# HDSC_HC32F146JX register map
Vendor: HDSC Co.Ltd; Series: ARMCM0P; File version: 1.2
CPU: CM0 r0p0, little endian, no MPU, no FPU, 3 interrupt priority bits
Registers are 8-bit, read-write, reset 0x0 unless marked. A register's access mark holds for its fields unless they carry their own. Offsets are from the block's base; [hi:lo] are bit positions; {n}, {i} and the like mark numbered series.

## EXTINT
Base 0x40030000
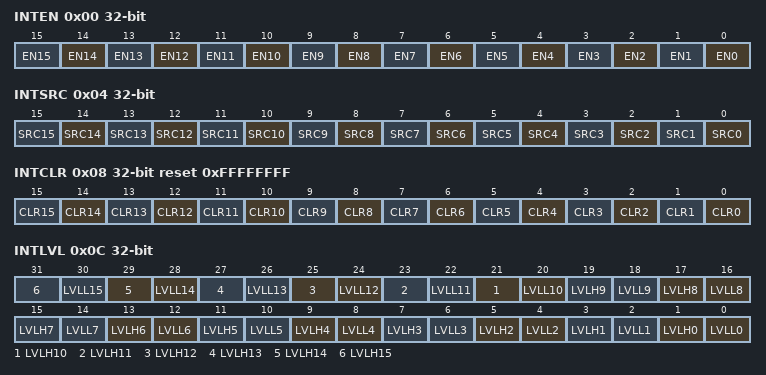
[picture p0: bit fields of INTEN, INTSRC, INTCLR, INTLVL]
0x00 INTEN 32-bit
  [n] EN{n} (n=0..15)
0x04 INTSRC 32-bit ro
  [n] SRC{n} (n=0..15)
0x08 INTCLR 32-bit reset 0xFFFFFFFF
  [n] CLR{n} (n=0..15)
0x0C INTLVL 32-bit
  [2n+1] LVLH{n} (n=0..15), [2n] LVLL{n} (n=0..15)
0x14 NMISRC 16-bit ro
  [0] SRC
0x18 NMICLR 16-bit reset 0x1
  [0] CLR

## FASTIO
Base 0xF8000000
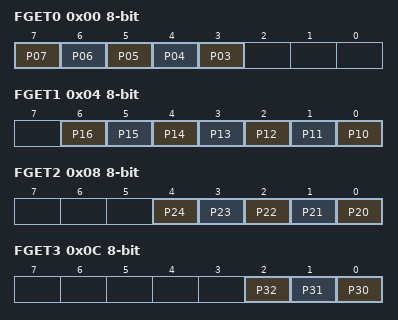
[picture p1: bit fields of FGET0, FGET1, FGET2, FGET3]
0x00 FGET0 ro
  [n] P{n:02} (n=3..7)
0x04 FGET1 ro
  [n-10] P{n} (n=10..16)
0x08 FGET2 ro
  [n-20] P{n} (n=20..24)
0x0C FGET3 ro
  [2] P32, [1] P31, [0] P30
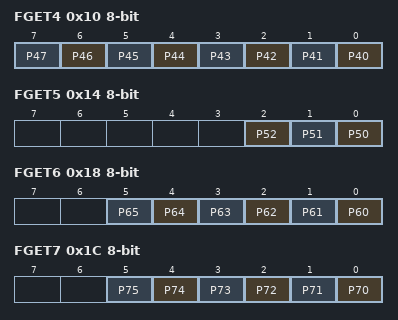
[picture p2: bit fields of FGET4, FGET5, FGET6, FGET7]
0x10 FGET4 ro
  [n-40] P{n} (n=40..47)
0x14 FGET5 ro
  [2] P52, [1] P51, [0] P50
0x18 FGET6 ro
  [n-60] P{n} (n=60..65)
0x1C FGET7 ro
  [n-70] P{n} (n=70..75)
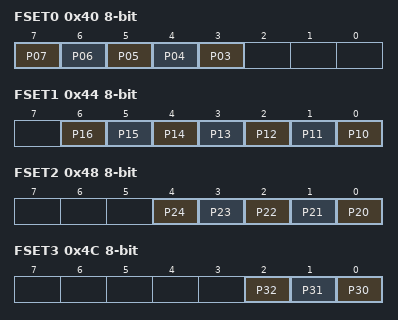
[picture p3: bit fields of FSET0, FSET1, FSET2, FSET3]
0x40 FSET0
  [n] P{n:02} (n=3..7)
0x44 FSET1
  [n-10] P{n} (n=10..16)
0x48 FSET2
  [n-20] P{n} (n=20..24)
0x4C FSET3
  [2] P32, [1] P31, [0] P30
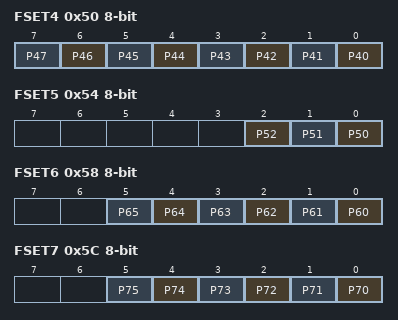
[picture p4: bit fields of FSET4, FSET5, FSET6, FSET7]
0x50 FSET4
  [n-40] P{n} (n=40..47)
0x54 FSET5
  [2] P52, [1] P51, [0] P50
0x58 FSET6
  [n-60] P{n} (n=60..65)
0x5C FSET7
  [n-70] P{n} (n=70..75)

## FLASH_IF
Base 0x40000000
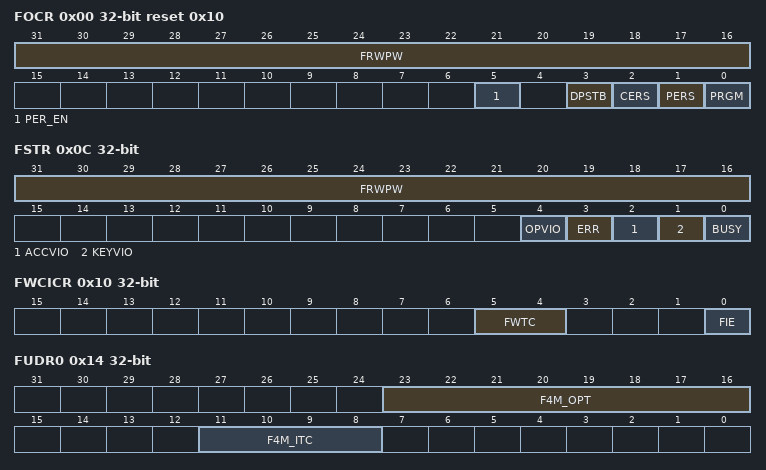
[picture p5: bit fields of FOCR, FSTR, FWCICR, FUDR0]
0x00 FOCR 32-bit reset 0x10
  [31:16] FRWPW, [5] PER_EN, [3] DPSTB, [2] CERS, [1] PERS, [0] PRGM
0x04 FLCR0 32-bit reset 0xFFFFFFFF
0x08 FLCR1 32-bit reset 0xFFFFFFFF
0x0C FSTR 32-bit
  [31:16] FRWPW, [4] OPVIO, [3] ERR, [2] ACCVIO, [1] KEYVIO, [0] BUSY ro
0x10 FWCICR 32-bit
  [5:4] FWTC, [0] FIE
0x14 FUDR0 32-bit ro
  [23:16] F4M_OPT, [11:8] F4M_ITC
0x24 TNVS 16-bit reset 0x18
  [8:0] TNVS
0x28 TPROG 16-bit reset 0x18
  [8:0] TPROG
0x2C TPGS 16-bit reset 0x18
  [8:0] TPGS
0x30 TRCVPGM 16-bit reset 0x18
  [8:0] TRCVPGM
0x34 TRCVPERS 16-bit reset 0x19
  [8:0] TRCVPERS
0x38 TRCVCERS 16-bit reset 0x7
  [8:0] TRCVCERS
0x3C TPERS 16-bit reset 0x10
  [8:0] TPERS
0x40 TCERS 16-bit reset 0x20
  [8:0] TCERS

## GPIO
Base 0x40033000
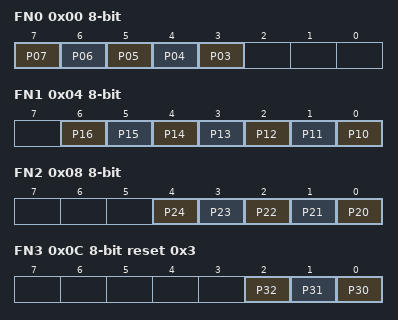
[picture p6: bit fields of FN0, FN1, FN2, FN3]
0x00 FN0
  [n] P{n:02} (n=3..7)
0x04 FN1
  [n-10] P{n} (n=10..16)
0x08 FN2
  [n-20] P{n} (n=20..24)
0x0C FN3 reset 0x3
  [2] P32, [1] P31, [0] P30
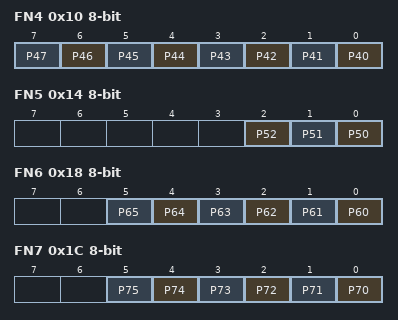
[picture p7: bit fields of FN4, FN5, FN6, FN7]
0x10 FN4
  [n-40] P{n} (n=40..47)
0x14 FN5
  [2] P52, [1] P51, [0] P50
0x18 FN6
  [n-60] P{n} (n=60..65)
0x1C FN7
  [n-70] P{n} (n=70..75)
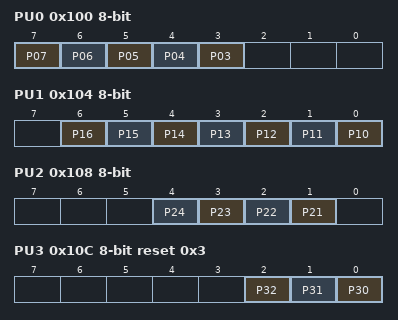
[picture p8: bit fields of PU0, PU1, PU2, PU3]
0x100 PU0
  [n] P{n:02} (n=3..7)
0x104 PU1
  [n-10] P{n} (n=10..16)
0x108 PU2
  [n-20] P{n} (n=21..24)
0x10C PU3 reset 0x3
  [2] P32, [1] P31, [0] P30
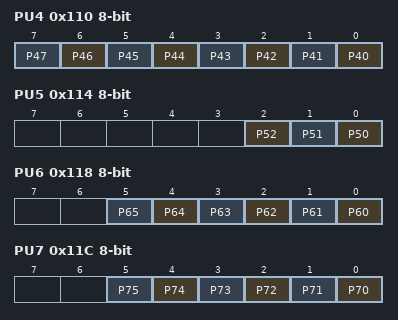
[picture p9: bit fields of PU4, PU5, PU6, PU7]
0x110 PU4
  [n-40] P{n} (n=40..47)
0x114 PU5
  [2] P52, [1] P51, [0] P50
0x118 PU6
  [n-60] P{n} (n=60..65)
0x11C PU7
  [n-70] P{n} (n=70..75)
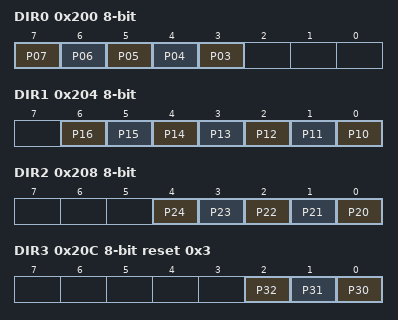
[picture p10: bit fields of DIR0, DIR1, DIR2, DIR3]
0x200 DIR0
  [n] P{n:02} (n=3..7)
0x204 DIR1
  [n-10] P{n} (n=10..16)
0x208 DIR2
  [n-20] P{n} (n=20..24)
0x20C DIR3 reset 0x3
  [2] P32, [1] P31, [0] P30
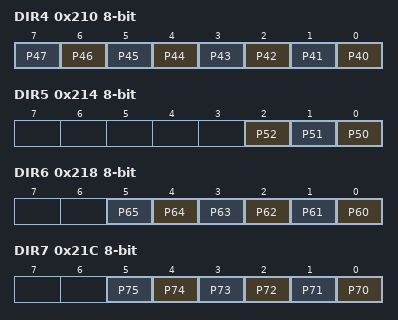
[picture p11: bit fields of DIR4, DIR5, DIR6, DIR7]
0x210 DIR4
  [n-40] P{n} (n=40..47)
0x214 DIR5
  [2] P52, [1] P51, [0] P50
0x218 DIR6
  [n-60] P{n} (n=60..65)
0x21C DIR7
  [n-70] P{n} (n=70..75)
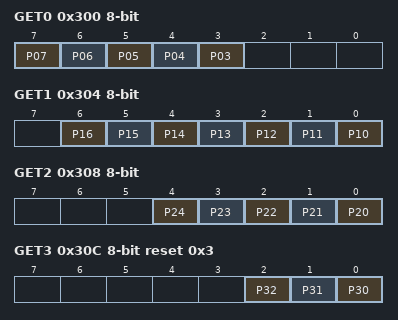
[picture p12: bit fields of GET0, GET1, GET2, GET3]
0x300 GET0
  [n] P{n:02} (n=3..7)
0x304 GET1
  [n-10] P{n} (n=10..16)
0x308 GET2
  [n-20] P{n} (n=20..24)
0x30C GET3 reset 0x3
  [2] P32, [1] P31, [0] P30
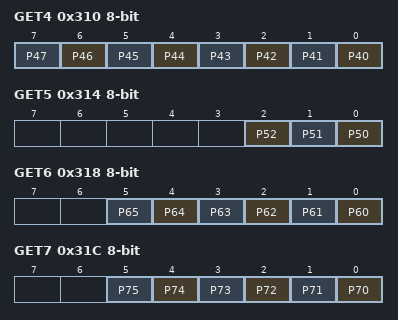
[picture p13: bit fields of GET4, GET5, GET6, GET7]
0x310 GET4
  [n-40] P{n} (n=40..47)
0x314 GET5
  [2] P52, [1] P51, [0] P50
0x318 GET6
  [n-60] P{n} (n=60..65)
0x31C GET7
  [n-70] P{n} (n=70..75)
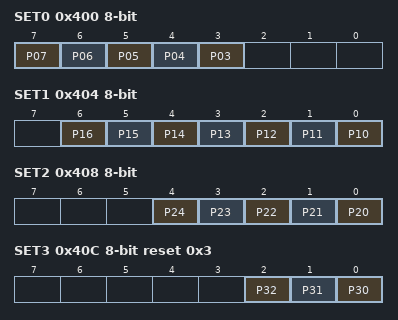
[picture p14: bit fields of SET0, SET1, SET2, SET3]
0x400 SET0
  [n] P{n:02} (n=3..7)
0x404 SET1
  [n-10] P{n} (n=10..16)
0x408 SET2
  [n-20] P{n} (n=20..24)
0x40C SET3 reset 0x3
  [2] P32, [1] P31, [0] P30
0x410 SET4
  [n-40] P{n} (n=40..47)
0x414 SET5
  [2] P52, [1] P51, [0] P50
0x418 SET6
  [n-60] P{n} (n=60..65)
0x41C SET7
  [n-70] P{n} (n=70..75)
0x500 ANALOG 32-bit
  [n] ADE{n:02} (n=0..23)
0x580 SPS
  [3:2] MAINCS, [1:0] SUBCS
0x600 FN_SEL00 32-bit reset 0x100
  [8] SWDEN, [2:1] CROUTE, [0] NMIS
0x604 FN_SEL01 32-bit
  [18] EXCK0S, [16] EMII0S, [12] EMII0C, [2n+1:2n] PWM{n:02}E (n=0..5)
0x608 FN_SEL02 32-bit
  [29:28] TIOB3S, [8n+3:8n+2] TIOA{n}E (n=0..3), [25:24] TIOA3S, [22:20] TIOB2S, [13:12] TIOB1S, [9:8] TIOA1S, [6:4] TIOB0S
0x610 FN_SEL04 32-bit
  [2n+1:2n] EINT{n:02}S (n=0..15)
0x61C FN_SEL07 32-bit
  [27:26] SCS50B, [25:24] SCK5B, [23:22] SOT5B, [21:20] SIN5S, [13:12] SCS41E, [11:10] SCS40B, [9:8] SCK4B, [7:6] SOT4B, [5:4] SIN4S, [3:2] CTS4S, [1:0] RTS4E
0x620 FN_SEL08 32-bit
  [15:14] SCS62E, [13:12] SCS61E, [11:10] SCS60B, [9:8] SCK6B, [7:6] SOT6B, [5:4] SIN6S, [3:2] CTS6S, [1:0] RTS6E
0x624 FN_SEL09 32-bit
  [24] ADTGS, [1:0] VCOE
0x700 ODR0
  [n] P{n:02} (n=3..7)
0x704 ODR1
  [n-10] P{n} (n=10..16)
0x708 ODR2
  [n-20] P{n} (n=20..24)
0x70C ODR3 reset 0x3
  [2] P32, [1] P31, [0] P30
0x710 ODR4
  [n-40] P{n} (n=40..47)
0x714 ODR5
  [2] P52, [1] P51, [0] P50
0x718 ODR6
  [n-60] P{n} (n=60..65)
0x71C ODR7
  [n-70] P{n} (n=70..75)
0x900 FSETE0
  [n] P{n:02} (n=3..7)
0x904 FSETE1
  [n-10] P{n} (n=10..16)
0x908 FSETE2
  [n-20] P{n} (n=20..24)
0x90C FSETE3 reset 0x3
  [2] P32, [1] P31, [0] P30
0x910 FSETE4
  [n-40] P{n} (n=40..47)
0x914 FSETE5
  [2] P52, [1] P51, [0] P50
0x918 FSETE6
  [n-60] P{n} (n=60..65)
0x91C FSETE7
  [n-70] P{n} (n=70..75)
